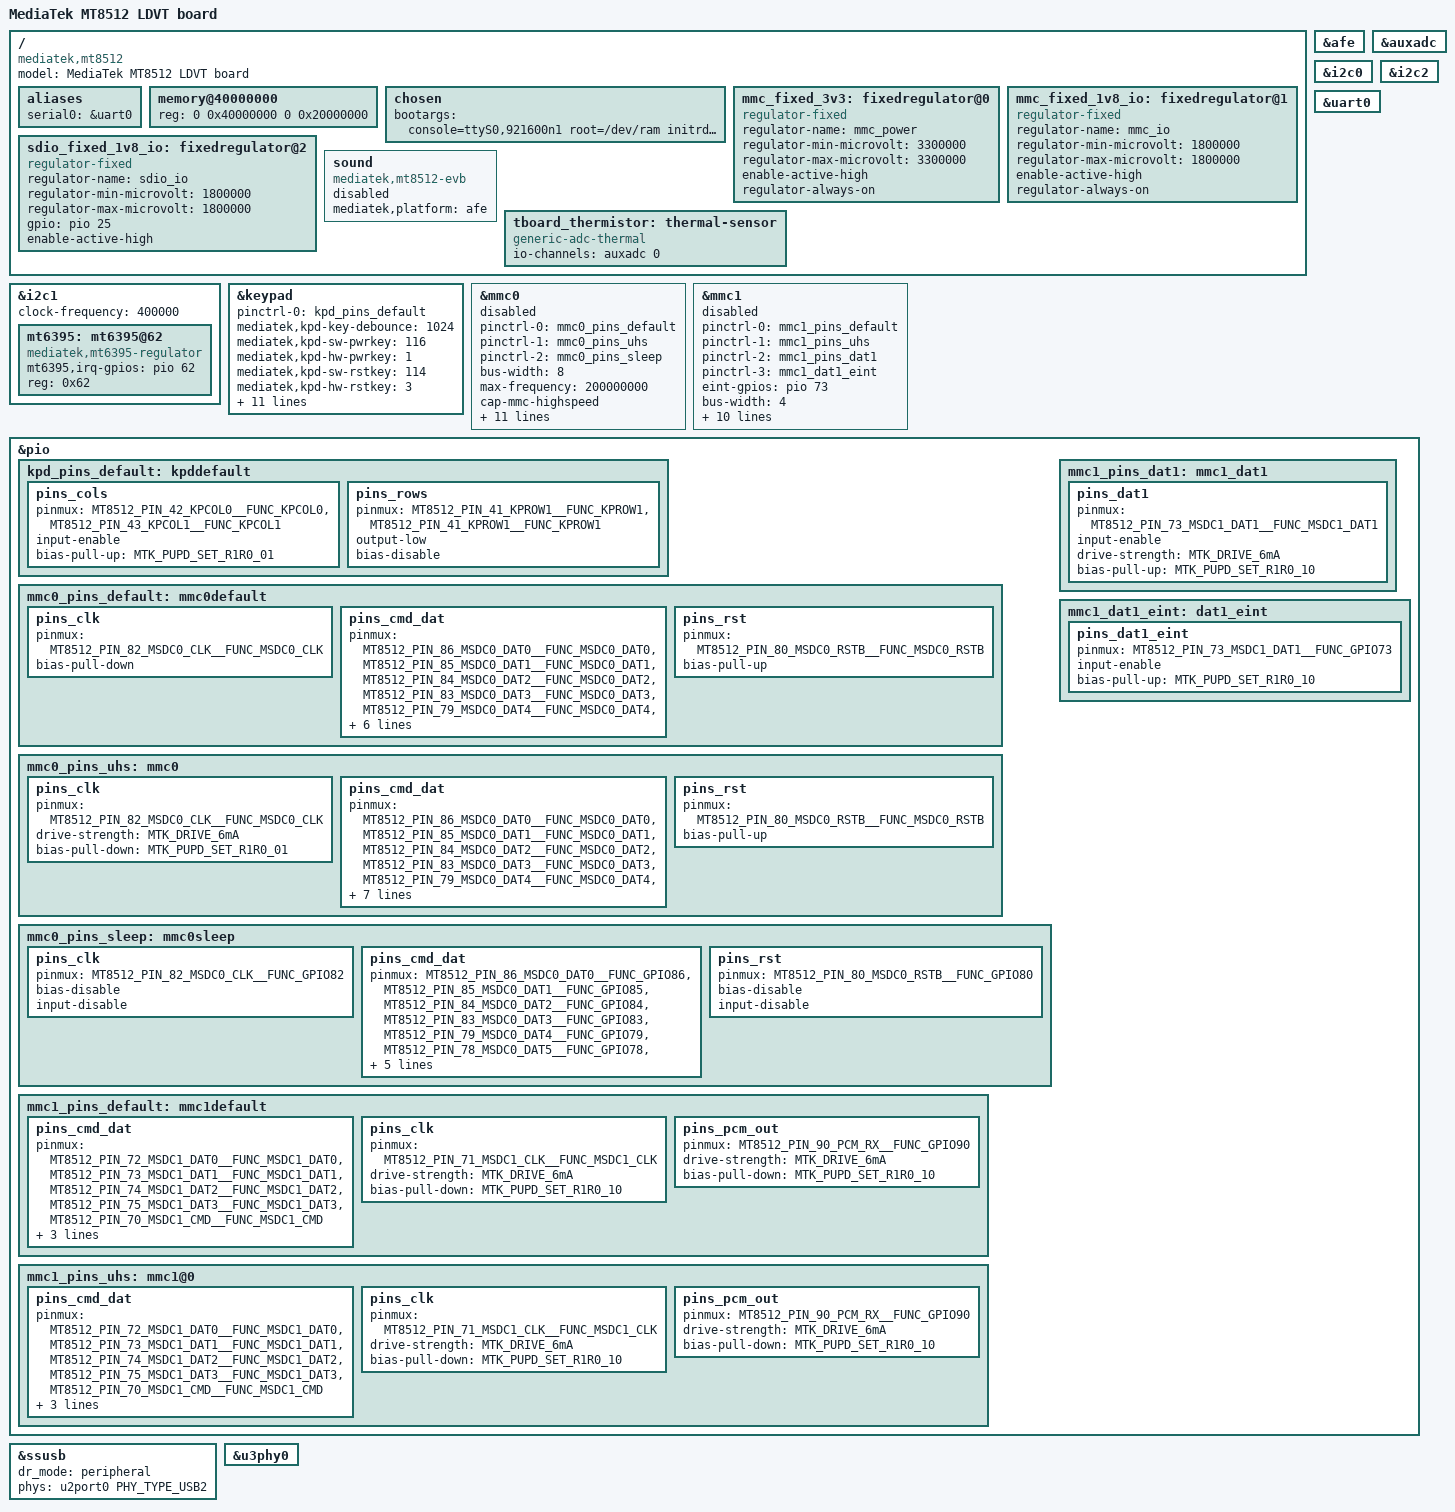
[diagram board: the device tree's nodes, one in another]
/*
 * Copyright (c) 2019 MediaTek Inc.
 *
 * SPDX-License-Identifier: (GPL-2.0 OR MIT)
 */

/dts-v1/;
#include "mt8512b.dtsi"

/ {
	model = "MediaTek MT8512 LDVT board";
	compatible = "mediatek,mt8512", "mediatek,mt8512";

	aliases {
		serial0 = &uart0;
	};

	memory@40000000 {
		device_type = "memory";
		reg = <0 0x40000000 0 0x20000000>;
	};

	chosen {
		bootargs = "console=ttyS0,921600n1 root=/dev/ram \
initrd=0x51000000,0x91EA22 earlycon=uart8250,mmio32,0x11002000 \
initcall_debug loglevel=8 androidboot.hardware=mt8512 \
firmware_class.path=/vendor/firmware clk_ignore_unused";
	};

	mmc_fixed_3v3: fixedregulator@0 {
		compatible = "regulator-fixed";
		regulator-name = "mmc_power";
		regulator-min-microvolt = <3300000>;
		regulator-max-microvolt = <3300000>;
		enable-active-high;
		regulator-always-on;
	};

	mmc_fixed_1v8_io: fixedregulator@1 {
		compatible = "regulator-fixed";
		regulator-name = "mmc_io";
		regulator-min-microvolt = <1800000>;
		regulator-max-microvolt = <1800000>;
		enable-active-high;
		regulator-always-on;
	};

	sdio_fixed_1v8_io: fixedregulator@2 {
		compatible = "regulator-fixed";
		regulator-name = "sdio_io";
		regulator-min-microvolt = <1800000>;
		regulator-max-microvolt = <1800000>;
		gpio = <&pio 25 0>;
		enable-active-high;
	};

	sound: sound {
		compatible = "mediatek,mt8512-evb";
		mediatek,platform = <&afe>;
		status = "disabled";
	};

	tboard_thermistor: thermal-sensor {
		compatible = "generic-adc-thermal";
		#thermal-sensor-cells = <0>;
		io-channels = <&auxadc 0>;
		io-channel-names = "sensor-channel";
	};
};

&afe {
	status = "okay";
};

&auxadc {
	status = "okay";
};

&i2c0 {
	status = "okay";
};

&i2c1 {
	status = "okay";
	clock-frequency = <400000>;

	mt6395: mt6395@62 {
		compatible = "mediatek,mt6395-regulator";
		mt6395,irq-gpios = <&pio 62 0x0>;
		reg = <0x62>;
		status = "okay";
	};
};

&i2c2 {
	status = "okay";
};

&keypad {
	pinctrl-names = "default";
	pinctrl-0 = <&kpd_pins_default>;
	status = "okay";
	mediatek,kpd-key-debounce = <1024>;
	mediatek,kpd-sw-pwrkey = <116>;
	mediatek,kpd-hw-pwrkey = <1>;
	mediatek,kpd-sw-rstkey  = <114>;
	mediatek,kpd-hw-rstkey = <3>;
	mediatek,kpd-use-extend-type = <0>;
	/*HW Keycode [0~3] -> Linux Keycode*/
	mediatek,kpd-hw-map-num = <72>;
	mediatek,kpd-hw-init-map =
			<115 0 0 0 0 0 0 0 0 0 0 0 0
			 0 0 0 0 0 0 0 0 0 0 0 0 0 0 0 0 0 0 0 0 0 0 0 0
			 0 0 0 0 0 0 0 0 0 0 0 0 0 0 0 0 0 0 0 0 0 0 0 0
			 0 0 0 0 0 0 0 0 0 0 0 >;
	mediatek,kpd-pwrkey-eint-gpio = <0>;
	mediatek,kpd-pwkey-gpio-din  = <0>;
	mediatek,kpd-hw-dl-key0 = <0>;
	mediatek,kpd-hw-dl-key1 = <3>;
	mediatek,kpd-hw-dl-key2 = <1>;
	mediatek,kpd-hw-recovery-key = <0>;
	mediatek,kpd-hw-factory-key  = <3>;
};

&uart0 {
	status = "okay";
};

&mmc0 {
	status = "disabled";
	pinctrl-names = "default", "state_uhs", "sleep";
	pinctrl-0 = <&mmc0_pins_default>;
	pinctrl-1 = <&mmc0_pins_uhs>;
	pinctrl-2 = <&mmc0_pins_sleep>;
	bus-width = <8>;
	max-frequency = <200000000>;
	cap-mmc-highspeed;
	mmc-hs200-1_8v;
	cap-cqe;
	cap-cqe_dcmd;
	vmmc-supply = <&mmc_fixed_3v3>;
	vqmmc-supply = <&mmc_fixed_1v8_io>;
	assigned-clocks = <&topckgen CLK_TOP_MSDC50_0_SEL>;
	assigned-clock-parents = <&topckgen CLK_TOP_MSDCPLL_D2>;
	non-removable;
	no-sd;
	no-sdio;
};

&mmc1 {
	pinctrl-names = "default", "state_uhs", "state_dat1", "state_eint";
	pinctrl-0 = <&mmc1_pins_default>;
	pinctrl-1 = <&mmc1_pins_uhs>;
	pinctrl-2 = <&mmc1_pins_dat1>;
	pinctrl-3 = <&mmc1_dat1_eint>;
	eint-gpios = <&pio 73 0>;
	status = "disabled";
	bus-width = <4>;
	max-frequency = <200000000>;
	cap-sd-highspeed;
	sd-uhs-sdr50;
	sd-uhs-sdr104;
	keep-power-in-suspend;
	enable-sdio-wakeup;
	cap-sdio-irq;
	non-removable;
	vmmc-supply = <&mmc_fixed_3v3>;
	vqmmc-supply = <&sdio_fixed_1v8_io>;
};

&pio {
	pinctrl-names = "default";

	kpd_pins_default: kpddefault {
		pins_cols {
			pinmux = <MT8512_PIN_42_KPCOL0__FUNC_KPCOL0>,
				 <MT8512_PIN_43_KPCOL1__FUNC_KPCOL1>;
			input-enable;
			bias-pull-up = <MTK_PUPD_SET_R1R0_01>;
		};

		pins_rows {
			pinmux = <MT8512_PIN_41_KPROW1__FUNC_KPROW1>,
				 <MT8512_PIN_41_KPROW1__FUNC_KPROW1>;
			output-low;
			bias-disable;
		};
	};

	mmc0_pins_default: mmc0default {
		pins_clk {
			pinmux = <MT8512_PIN_82_MSDC0_CLK__FUNC_MSDC0_CLK>;
			bias-pull-down;
		};

		pins_cmd_dat {
			pinmux = <MT8512_PIN_86_MSDC0_DAT0__FUNC_MSDC0_DAT0>,
				 <MT8512_PIN_85_MSDC0_DAT1__FUNC_MSDC0_DAT1>,
				 <MT8512_PIN_84_MSDC0_DAT2__FUNC_MSDC0_DAT2>,
				 <MT8512_PIN_83_MSDC0_DAT3__FUNC_MSDC0_DAT3>,
				 <MT8512_PIN_79_MSDC0_DAT4__FUNC_MSDC0_DAT4>,
				 <MT8512_PIN_78_MSDC0_DAT5__FUNC_MSDC0_DAT5>,
				 <MT8512_PIN_77_MSDC0_DAT6__FUNC_MSDC0_DAT6>,
				 <MT8512_PIN_76_MSDC0_DAT7__FUNC_MSDC0_DAT7>,
				 <MT8512_PIN_81_MSDC0_CMD__FUNC_MSDC0_CMD>;
			input-enable;
			bias-pull-up;
		};

		pins_rst {
			pinmux = <MT8512_PIN_80_MSDC0_RSTB__FUNC_MSDC0_RSTB>;
			bias-pull-up;
		};
	};

	mmc0_pins_uhs: mmc0 {
		pins_clk {
			pinmux = <MT8512_PIN_82_MSDC0_CLK__FUNC_MSDC0_CLK>;
			drive-strength = <MTK_DRIVE_6mA>;
			bias-pull-down = <MTK_PUPD_SET_R1R0_01>;
		};

		pins_cmd_dat {
			pinmux = <MT8512_PIN_86_MSDC0_DAT0__FUNC_MSDC0_DAT0>,
				 <MT8512_PIN_85_MSDC0_DAT1__FUNC_MSDC0_DAT1>,
				 <MT8512_PIN_84_MSDC0_DAT2__FUNC_MSDC0_DAT2>,
				 <MT8512_PIN_83_MSDC0_DAT3__FUNC_MSDC0_DAT3>,
				 <MT8512_PIN_79_MSDC0_DAT4__FUNC_MSDC0_DAT4>,
				 <MT8512_PIN_78_MSDC0_DAT5__FUNC_MSDC0_DAT5>,
				 <MT8512_PIN_77_MSDC0_DAT6__FUNC_MSDC0_DAT6>,
				 <MT8512_PIN_76_MSDC0_DAT7__FUNC_MSDC0_DAT7>,
				 <MT8512_PIN_81_MSDC0_CMD__FUNC_MSDC0_CMD>;
			input-enable;
			drive-strength = <MTK_DRIVE_6mA>;
			bias-pull-up = <MTK_PUPD_SET_R1R0_01>;
		};

		pins_rst {
			pinmux = <MT8512_PIN_80_MSDC0_RSTB__FUNC_MSDC0_RSTB>;
			bias-pull-up;
		};
	};

	mmc0_pins_sleep: mmc0sleep {
		pins_clk {
			pinmux = <MT8512_PIN_82_MSDC0_CLK__FUNC_GPIO82>;
			bias-disable;
			input-disable;
		};

		pins_cmd_dat {
			pinmux = <MT8512_PIN_86_MSDC0_DAT0__FUNC_GPIO86>,
				 <MT8512_PIN_85_MSDC0_DAT1__FUNC_GPIO85>,
				 <MT8512_PIN_84_MSDC0_DAT2__FUNC_GPIO84>,
				 <MT8512_PIN_83_MSDC0_DAT3__FUNC_GPIO83>,
				 <MT8512_PIN_79_MSDC0_DAT4__FUNC_GPIO79>,
				 <MT8512_PIN_78_MSDC0_DAT5__FUNC_GPIO78>,
				 <MT8512_PIN_77_MSDC0_DAT6__FUNC_GPIO77>,
				 <MT8512_PIN_76_MSDC0_DAT7__FUNC_GPIO76>,
				 <MT8512_PIN_81_MSDC0_CMD__FUNC_GPIO81>;
			bias-disable;
			input-disable;
		};

		pins_rst {
			pinmux = <MT8512_PIN_80_MSDC0_RSTB__FUNC_GPIO80>;
			bias-disable;
			input-disable;
		};
	};

	mmc1_pins_default: mmc1default {
		pins_cmd_dat {
			pinmux = <MT8512_PIN_72_MSDC1_DAT0__FUNC_MSDC1_DAT0>,
			       <MT8512_PIN_73_MSDC1_DAT1__FUNC_MSDC1_DAT1>,
			       <MT8512_PIN_74_MSDC1_DAT2__FUNC_MSDC1_DAT2>,
			       <MT8512_PIN_75_MSDC1_DAT3__FUNC_MSDC1_DAT3>,
			       <MT8512_PIN_70_MSDC1_CMD__FUNC_MSDC1_CMD>;
			input-enable;
			drive-strength = <MTK_DRIVE_6mA>;
			bias-pull-up = <MTK_PUPD_SET_R1R0_10>;
		};

		pins_clk {
			pinmux = <MT8512_PIN_71_MSDC1_CLK__FUNC_MSDC1_CLK>;
			drive-strength = <MTK_DRIVE_6mA>;
			bias-pull-down = <MTK_PUPD_SET_R1R0_10>;
		};

		pins_pcm_out {
			pinmux = <MT8512_PIN_90_PCM_RX__FUNC_GPIO90>;
			drive-strength = <MTK_DRIVE_6mA>;
			bias-pull-down = <MTK_PUPD_SET_R1R0_10>;
		};
	};

	mmc1_pins_uhs: mmc1@0 {
		pins_cmd_dat {
			pinmux = <MT8512_PIN_72_MSDC1_DAT0__FUNC_MSDC1_DAT0>,
			       <MT8512_PIN_73_MSDC1_DAT1__FUNC_MSDC1_DAT1>,
			       <MT8512_PIN_74_MSDC1_DAT2__FUNC_MSDC1_DAT2>,
			       <MT8512_PIN_75_MSDC1_DAT3__FUNC_MSDC1_DAT3>,
			       <MT8512_PIN_70_MSDC1_CMD__FUNC_MSDC1_CMD>;
			input-enable;
			drive-strength = <MTK_DRIVE_6mA>;
			bias-pull-up = <MTK_PUPD_SET_R1R0_10>;
		};

		pins_clk {
			pinmux = <MT8512_PIN_71_MSDC1_CLK__FUNC_MSDC1_CLK>;
			drive-strength = <MTK_DRIVE_6mA>;
			bias-pull-down = <MTK_PUPD_SET_R1R0_10>;
		};

		pins_pcm_out {
			pinmux = <MT8512_PIN_90_PCM_RX__FUNC_GPIO90>;
			drive-strength = <MTK_DRIVE_6mA>;
			bias-pull-down = <MTK_PUPD_SET_R1R0_10>;
		};
	};

	mmc1_pins_dat1: mmc1_dat1 {
		pins_dat1 {
			pinmux = <MT8512_PIN_73_MSDC1_DAT1__FUNC_MSDC1_DAT1>;
			input-enable;
			drive-strength = <MTK_DRIVE_6mA>;
			bias-pull-up = <MTK_PUPD_SET_R1R0_10>;
		};
	};

	mmc1_dat1_eint: dat1_eint {
		pins_dat1_eint {
			pinmux = <MT8512_PIN_73_MSDC1_DAT1__FUNC_GPIO73>;
			input-enable;
			bias-pull-up = <MTK_PUPD_SET_R1R0_10>;
		};
	};
};

&ssusb {
	dr_mode = "peripheral";
	phys = <&u2port0 PHY_TYPE_USB2>;
	status="okay";
};

&u3phy0 {
	status = "okay";
};

#include "mt6395.dtsi"
